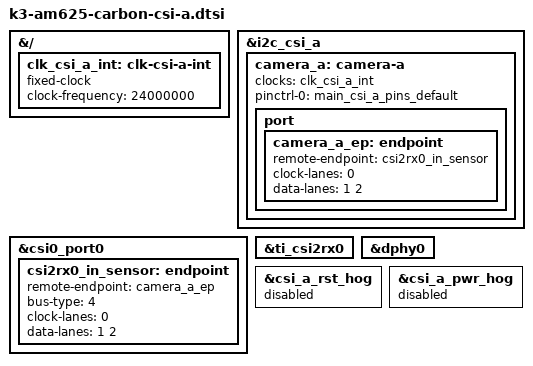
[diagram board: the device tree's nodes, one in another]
// SPDX-License-Identifier: GPL-2.0
/*
 * Digilent Pcam 5C 5MP OV5640 camera module
 *
 * Copyright (C) 2024 Ezurio LLC
 */

#include <dt-bindings/gpio/gpio.h>

&{/} {
	/* On Camera module oscillator */
	clk_csi_a_int: clk-csi-a-int {
		compatible = "fixed-clock";
		#clock-cells = <0>;
		clock-frequency = <24000000>;
	};
};

&i2c_csi_a {
	#address-cells = <1>;
	#size-cells = <0>;

	camera_a: camera-a {
		clocks = <&clk_csi_a_int>; /* On Camera module */
		clock-names = "xclk";

		pinctrl-names = "default";
		pinctrl-0 = <&main_csi_a_pins_default>;

		port {
			camera_a_ep: endpoint {
				remote-endpoint = <&csi2rx0_in_sensor>;
				clock-lanes = <0>;
				data-lanes = <1 2>;
			};
		};
	};
};

&csi0_port0 {
	status = "okay";

	csi2rx0_in_sensor: endpoint {
		remote-endpoint = <&camera_a_ep>;
		bus-type = <4>; /* CSI2 DPHY. */
		clock-lanes = <0>;
		data-lanes = <1 2>;
	};
};

&ti_csi2rx0 {
	status = "okay";
};

&dphy0 {
	status = "okay";
};

&csi_a_rst_hog {
	status = "disabled";
};

&csi_a_pwr_hog {
	status = "disabled";
};
